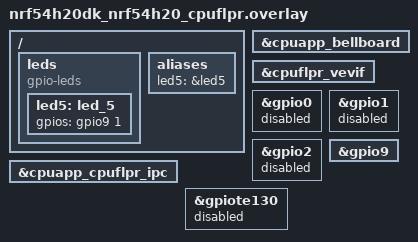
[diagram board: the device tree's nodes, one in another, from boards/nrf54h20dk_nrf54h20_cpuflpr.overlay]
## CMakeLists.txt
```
#
# Copyright (c) 2024 Nordic Semiconductor ASA
#
# SPDX-License-Identifier: LicenseRef-Nordic-5-Clause
#

cmake_minimum_required(VERSION 3.20.0)

find_package(Zephyr REQUIRED HINTS $ENV{ZEPHYR_BASE})
project(sdp_gpio)

sdp_assembly_install(app "${CMAKE_SOURCE_DIR}/src/hrt/hrt.c")

target_sources(app PRIVATE src/main.c)

target_sources_ifdef(CONFIG_SDP_GPIO_BACKEND_ICMSG app PRIVATE src/backend/backend_icmsg.c)
target_sources_ifdef(CONFIG_SDP_GPIO_BACKEND_ICBMSG app PRIVATE src/backend/backend_icmsg.c)
target_sources_ifdef(CONFIG_SDP_GPIO_BACKEND_MBOX app PRIVATE  src/backend/backend_mbox.c)
```

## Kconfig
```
choice SDP_GPIO_BACKEND
	prompt "Backend"
	default SDP_GPIO_BACKEND_ICMSG

config SDP_GPIO_BACKEND_MBOX
	bool "mbox"

config SDP_GPIO_BACKEND_ICMSG
	bool "icmsg"
	select IPC_SERVICE

config SDP_GPIO_BACKEND_ICBMSG
	bool "icbmsg"
	select IPC_SERVICE

endchoice

rsource "../Kconfig"
source "Kconfig.zephyr"
```

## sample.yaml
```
sample:
  name: SDP GPIO application
  description: SDP GPIO application
common:
  integration_platforms:
    - nrf54l15dk/nrf54l15/cpuflpr
tests:
  applications.sdp.gpio.mbox:
    build_only: true
    sysbuild: true
    platform_allow: nrf54l15dk/nrf54l15/cpuflpr
    tags:
      - ci_build
      - sysbuild
      - gpio
    required_snippets:
      - sdp-gpio-mbox

  applications.sdp.gpio.icmsg:
    build_only: true
    sysbuild: true
    platform_allow: nrf54l15dk/nrf54l15/cpuflpr
    tags:
      - ci_build
      - sysbuild
      - gpio
    required_snippets:
      - sdp-gpio-icmsg

  applications.sdp.gpio.icbmsg:
    sysbuild: true
    build_only: true
    platform_allow: nrf54l15dk/nrf54l15/cpuflpr
    tags:
      - ci_build
      - sysbuild
      - gpio
    required_snippets:
      - sdp-gpio-icbmsg
```

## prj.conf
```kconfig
CONFIG_MBOX=y
CONFIG_GPIO=y  

CONFIG_GPIO_NRFX_INTERRUPT=n
CONFIG_NRFX_GPIOTE130=n
CONFIG_NRFX_GPIOTE131=n
```

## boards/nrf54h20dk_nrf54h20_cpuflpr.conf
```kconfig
# Single-threaded
CONFIG_MULTITHREADING=n
CONFIG_KERNEL_MEM_POOL=n
CONFIG_LOG=n

# Drivers and peripherals
CONFIG_I2C=n
CONFIG_WATCHDOG=n
CONFIG_PINCTRL=n
CONFIG_SPI=n
CONFIG_SERIAL=n
CONFIG_FLASH=n

# Power management
CONFIG_PM=n

# Interrupts
CONFIG_DYNAMIC_INTERRUPTS=n
CONFIG_IRQ_OFFLOAD=n

# Memory protection
CONFIG_THREAD_STACK_INFO=n
CONFIG_THREAD_CUSTOM_DATA=n
CONFIG_FPU=n

# Boot
CONFIG_BOOT_BANNER=n

# Console
CONFIG_CONSOLE=n
CONFIG_UART_CONSOLE=n
CONFIG_STDOUT_CONSOLE=n
CONFIG_PRINTK=n
CONFIG_EARLY_CONSOLE=n

# Build
CONFIG_SIZE_OPTIMIZATIONS=y

# No timer support in the kernel
CONFIG_SYS_CLOCK_EXISTS=n

CONFIG_OUTPUT_DISASSEMBLY=y
CONFIG_COMMON_LIBC_MALLOC=n
```

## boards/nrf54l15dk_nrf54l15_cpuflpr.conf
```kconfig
# Single-threaded
CONFIG_MULTITHREADING=n
CONFIG_KERNEL_MEM_POOL=n
CONFIG_LOG=n

# Drivers and peripherals
CONFIG_I2C=n
CONFIG_WATCHDOG=n
CONFIG_GPIO=n
CONFIG_PINCTRL=n
CONFIG_SPI=n
CONFIG_SERIAL=n
CONFIG_FLASH=n

# Power management
CONFIG_PM=n

# Interrupts
CONFIG_DYNAMIC_INTERRUPTS=n
CONFIG_IRQ_OFFLOAD=n

# Memory protection
CONFIG_THREAD_STACK_INFO=n
CONFIG_THREAD_CUSTOM_DATA=n
CONFIG_FPU=n

# Boot
CONFIG_BOOT_BANNER=n
CONFIG_NCS_BOOT_BANNER=n

# Console
CONFIG_CONSOLE=n
CONFIG_UART_CONSOLE=n
CONFIG_STDOUT_CONSOLE=n
CONFIG_PRINTK=n
CONFIG_EARLY_CONSOLE=n

# Build
CONFIG_SIZE_OPTIMIZATIONS=y

# No timer support in the kernel
CONFIG_SYS_CLOCK_EXISTS=n

CONFIG_OUTPUT_DISASSEMBLY=y
CONFIG_COMMON_LIBC_MALLOC=n
```

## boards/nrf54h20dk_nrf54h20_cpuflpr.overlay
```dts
/*
 * Copyright (c) 2024 Nordic Semiconductor ASA
 *
 * SPDX-License-Identifier: LicenseRef-Nordic-5-Clause
 */

&cpuapp_bellboard {
	status = "okay";
};

&cpuflpr_vevif {
	status = "okay";
};

ipc0: &cpuapp_cpuflpr_ipc {
	status = "okay";
};

&gpio0 {
	status = "disabled";
};

&gpio1 {
	status = "disabled";
};

&gpio2 {
	status = "disabled";
};

&gpio9 {
	status = "okay";
};

&gpiote130 {
	status = "disabled";
	/delete-property/gpiote-instance;
};

/ {
	leds {
 		compatible = "gpio-leds";
 
 		led5: led_5 {
 			gpios = <&gpio9 1 GPIO_ACTIVE_HIGH>;
		};
 	};

	aliases {
		led5 = &led5;
	};
};
```

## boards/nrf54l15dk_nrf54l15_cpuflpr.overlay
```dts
/*
 * Copyright (c) 2024 Nordic Semiconductor ASA
 *
 * SPDX-License-Identifier: LicenseRef-Nordic-5-Clause
 */

&cpuflpr_vevif_rx {
	status = "okay";
	interrupts = <16 NRF_DEFAULT_IRQ_PRIORITY>;
	nordic,tasks = <1>;
	nordic,tasks-mask = <0x00010000>;
};

&cpuflpr_vevif_tx {
	status = "okay";
};

&gpio0 {
	status = "disabled";
};

&gpio1 {
	status = "disabled";
};

&gpio2 {
	status = "disabled";
};

&gpiote20 {
	status = "disabled";
};

&gpiote30 {
	status = "disabled";
};

&grtc {
	status = "disabled";
};

&uart20 {
	status = "disabled";
};

&uart30 {
	status = "disabled";
};

&pwm20 {
	status = "disabled";
};
```

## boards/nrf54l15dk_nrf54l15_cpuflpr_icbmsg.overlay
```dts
/*
 * Copyright (c) 2024 Nordic Semiconductor ASA
 *
 * SPDX-License-Identifier: LicenseRef-Nordic-5-Clause
 */

/ {
	soc {
		reserved-memory {
			#address-cells = <1>;
			#size-cells = <1>;

			sram_tx: memory@2003b800 {
				reg = <0x2003b800 0x0800>;
			};

			sram_rx: memory@2003c000 {
				reg = <0x2003c000 0x0800>;
			};
		};
	};

	ipc {
		ipc0: ipc0 {
			compatible = "zephyr,ipc-icbmsg";
			tx-region = <&sram_tx>;
			rx-region = <&sram_rx>;
			tx-blocks = <18>;
			rx-blocks = <16>;
			mboxes = <&cpuflpr_vevif_rx 16>, <&cpuflpr_vevif_tx 20>;
			mbox-names = "rx", "tx";
			status = "okay";
		};
	};
};

&cpuflpr_sram {
	reg = <0x2003c800 DT_SIZE_K(14)>;
	ranges = <0x0 0x2003c800 0x3800>;
};
```

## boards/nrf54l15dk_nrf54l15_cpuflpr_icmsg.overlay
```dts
/*
 * Copyright (c) 2024 Nordic Semiconductor ASA
 *
 * SPDX-License-Identifier: LicenseRef-Nordic-5-Clause
 */

/ {
	soc {
		reserved-memory {
			#address-cells = <1>;
			#size-cells = <1>;

			sram_tx: memory@2003c000 {
				reg = <0x2003c000 0x0800>;
			};

			sram_rx: memory@2003c800 {
				reg = <0x2003c800 0x0800>;
			};
		};
	};

	ipc {
		ipc0: ipc0 {
			compatible = "zephyr,ipc-icmsg";
			tx-region = <&sram_tx>;
			rx-region = <&sram_rx>;
			mboxes = <&cpuflpr_vevif_rx 16>, <&cpuflpr_vevif_tx 20>;
			mbox-names = "rx", "tx";
			status = "okay";
		};
	};
};

&cpuflpr_sram {
	reg = <0x2003d000 DT_SIZE_K(12)>;
	ranges = <0x0 0x2003d000 0x3000>;
};
```

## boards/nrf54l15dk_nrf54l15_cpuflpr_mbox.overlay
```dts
/*
 * Copyright (c) 2024 Nordic Semiconductor ASA
 *
 * SPDX-License-Identifier: LicenseRef-Nordic-5-Clause
 */

/ {
	soc {
		reserved-memory {
			#address-cells = <1>;
			#size-cells = <1>;

			sram_tx: memory@2003c000 {
				reg = <0x2003c000 0x0800>;
			};

			sram_rx: memory@2003c800 {
				reg = <0x2003c800 0x0800>;
			};
		};
	};

	mbox_consumer: mbox_consumer {
		compatible = "vnd,mbox-consumer";
		mboxes = <&cpuflpr_vevif_rx 16>, <&cpuflpr_vevif_tx 20>;
		mbox-names = "rx", "tx";
	};
};

&cpuflpr_rram {
	reg = <0x17a000 DT_SIZE_K(12)>;
};

&cpuflpr_code_partition {
	reg = <0x0 DT_SIZE_K(12)>;
};

&cpuflpr_sram {
	reg = <0x2003d000 DT_SIZE_K(12)>;
	ranges = <0x0 0x2003d000 0x3000>;
};
```

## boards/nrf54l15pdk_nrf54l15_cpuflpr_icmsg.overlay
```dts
/*
 * Copyright (c) 2024 Nordic Semiconductor ASA
 *
 * SPDX-License-Identifier: LicenseRef-Nordic-5-Clause
 */

/ {
	ipc {
		ipc0: ipc0 {
			compatible = "zephyr,ipc-icmsg";
			tx-region = <&sram_tx>;
			rx-region = <&sram_rx>;
			mboxes = <&cpuflpr_vevif_rx 16>, <&cpuflpr_vevif_tx 15>;
			mbox-names = "rx", "tx";
			status = "okay";
		};
	};
};
```

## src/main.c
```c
/*
 * Copyright (c) 2024 Nordic Semiconductor ASA
 *
 * SPDX-License-Identifier: LicenseRef-Nordic-5-Clause
 */

#include "./backend/backend.h"
#include <zephyr/kernel.h>
#include <zephyr/drivers/gpio.h>
#include <zephyr/dt-bindings/gpio/nordic-nrf-gpio.h>
#include <drivers/gpio/nrfe_gpio.h>
#include <hal/nrf_vpr_csr.h>
#include <hal/nrf_vpr_csr_vio.h>
#include <haly/nrfy_gpio.h>

#include <zephyr/drivers/gpio.h>
#define LED5_NODE DT_ALIAS(led5)
static const struct gpio_dt_spec led = GPIO_DT_SPEC_GET(LED5_NODE, gpios);

static nrf_gpio_pin_pull_t get_pull(gpio_flags_t flags)
{
	if (flags & GPIO_PULL_UP) {
		return NRF_GPIO_PIN_PULLUP;
	} else if (flags & GPIO_PULL_DOWN) {
		return NRF_GPIO_PIN_PULLDOWN;
	}

	return NRF_GPIO_PIN_NOPULL;
}

static int gpio_nrfe_pin_configure(uint8_t port, uint16_t pin, uint32_t flags)
{
	if (port != 2) {
		return -EINVAL;
	}

	uint32_t abs_pin = NRF_GPIO_PIN_MAP(port, pin);
	nrf_gpio_pin_pull_t pull = get_pull(flags);
	nrf_gpio_pin_drive_t drive;

	switch (flags & (NRF_GPIO_DRIVE_MSK | GPIO_OPEN_DRAIN)) {
	case NRF_GPIO_DRIVE_S0S1:
		drive = NRF_GPIO_PIN_S0S1;
		break;
	case NRF_GPIO_DRIVE_S0H1:
		drive = NRF_GPIO_PIN_S0H1;
		break;
	case NRF_GPIO_DRIVE_H0S1:
		drive = NRF_GPIO_PIN_H0S1;
		break;
	case NRF_GPIO_DRIVE_H0H1:
		drive = NRF_GPIO_PIN_H0H1;
		break;
	case NRF_GPIO_DRIVE_S0 | GPIO_OPEN_DRAIN:
		drive = NRF_GPIO_PIN_S0D1;
		break;
	case NRF_GPIO_DRIVE_H0 | GPIO_OPEN_DRAIN:
		drive = NRF_GPIO_PIN_H0D1;
		break;
	case NRF_GPIO_DRIVE_S1 | GPIO_OPEN_SOURCE:
		drive = NRF_GPIO_PIN_D0S1;
		break;
	case NRF_GPIO_DRIVE_H1 | GPIO_OPEN_SOURCE:
		drive = NRF_GPIO_PIN_D0H1;
		break;
	default:
		return -EINVAL;
	}

	if (flags & GPIO_OUTPUT_INIT_HIGH) {
		uint16_t outs = nrf_vpr_csr_vio_out_get();

		nrf_vpr_csr_vio_out_set(outs | (BIT(pin)));
	} else if (flags & GPIO_OUTPUT_INIT_LOW) {
		uint16_t outs = nrf_vpr_csr_vio_out_get();

		nrf_vpr_csr_vio_out_set(outs & ~(BIT(pin)));
	}

	nrf_gpio_pin_dir_t dir =
		(flags & GPIO_OUTPUT) ? NRF_GPIO_PIN_DIR_OUTPUT : NRF_GPIO_PIN_DIR_INPUT;
	nrf_gpio_pin_input_t input =
		(flags & GPIO_INPUT) ? NRF_GPIO_PIN_INPUT_CONNECT : NRF_GPIO_PIN_INPUT_DISCONNECT;

	/* Reconfigure the GPIO pin with the specified pull-up/pull-down configuration and drive
	 * strength.
	 */
	nrfy_gpio_reconfigure(abs_pin, &dir, &input, &pull, &drive, NULL);

	if (dir == NRF_GPIO_PIN_DIR_OUTPUT) {
		nrf_vpr_csr_vio_dir_set(nrf_vpr_csr_vio_dir_get() | (BIT(pin)));
	}

	/* Take control of the pin */
	nrfy_gpio_pin_control_select(abs_pin, NRF_GPIO_PIN_SEL_VPR);

	return 0;
}

static void gpio_nrfe_port_set_bits_raw(uint16_t set_mask)
{
	uint16_t outs = nrf_vpr_csr_vio_out_get();

	nrf_vpr_csr_vio_out_set(outs | set_mask);
}

static void gpio_nrfe_port_clear_bits_raw(uint16_t clear_mask)
{
	uint16_t outs = nrf_vpr_csr_vio_out_get();

	nrf_vpr_csr_vio_out_set(outs & ~clear_mask);
}

static void gpio_nrfe_port_toggle_bits(uint16_t toggle_mask)
{
	nrf_vpr_csr_vio_out_toggle_set(toggle_mask);
}

void process_packet(nrfe_gpio_data_packet_t *packet)
{
	if (packet->port != 2) {

		return;
	}

	switch (packet->opcode) {
	case NRFE_GPIO_PIN_CONFIGURE: {
		gpio_nrfe_pin_configure(packet->port, packet->pin, packet->flags);
		break;
	}
	case NRFE_GPIO_PIN_CLEAR: {
		gpio_nrfe_port_clear_bits_raw(packet->pin);
		break;
	}
	case NRFE_GPIO_PIN_SET: {
		gpio_nrfe_port_set_bits_raw(packet->pin);
		break;
	}
	case NRFE_GPIO_PIN_TOGGLE: {
		gpio_pin_toggle_dt(&led);
		gpio_nrfe_port_toggle_bits(packet->pin);
		break;
	}
	default: {
		break;
	}
	}
}

int main(void)
{
	int ret;

	if (!gpio_is_ready_dt(&led)) {
		return 0;
	}

	ret = gpio_pin_configure_dt(&led, GPIO_OUTPUT_ACTIVE);
	if (ret < 0) {
		return 0;
	}

	ret = backend_init(process_packet);
	if (ret < 0) {
		return 0;
	}

	if (!nrf_vpr_csr_rtperiph_enable_check()) {
		nrf_vpr_csr_rtperiph_enable_set(true);
	}

	while (true) {
		k_cpu_idle();
	}

	return 0;
}
```

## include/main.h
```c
/*
 * Copyright (c) 2024 Nordic Semiconductor ASA
 *
 * SPDX-License-Identifier: LicenseRef-Nordic-5-Clause
 */

#ifndef MAIN_H__
#define MAIN_H__

#include <zephyr/kernel.h>
#include <drivers/gpio/nrfe_gpio.h>

#if !defined(CONFIG_GPIO_NRFE_EGPIO_BACKEND_ICMSG) &&    \
	!defined(CONFIG_GPIO_NRFE_EGPIO_BACKEND_MBOX) && \
	!defined(CONFIG_GPIO_NRFE_EGPIO_BACKEND_ICBMSG)
#error "Define communication backend type"
#endif

void process_packet(nrfe_gpio_data_packet_t *packet);
int backend_init(void);

#endif /* MAIN_H__ */
```

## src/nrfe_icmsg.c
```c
/*
 * Copyright (c) 2024 Nordic Semiconductor ASA
 *
 * SPDX-License-Identifier: LicenseRef-Nordic-5-Clause
 */

#include "../include/main.h"
#include <zephyr/ipc/ipc_service.h>

static struct ipc_ept ep;

volatile uint32_t bound_sem = 1;

static void ep_bound(void *priv)
{
	bound_sem = 0;
}

static void ep_recv(const void *data, size_t len, void *priv)
{
	(void)len;
	(void)priv;

	process_packet((nrfe_gpio_data_packet_t *)data);
}

static struct ipc_ept_cfg ep_cfg = {
	.cb = {
		.bound = ep_bound,
		.received = ep_recv,
	},
};

int backend_init(void)
{
	int ret = 0;
	const struct device *ipc0_instance;
	volatile uint32_t delay = 0;

#if !defined(CONFIG_SYS_CLOCK_EXISTS)
	/* Wait a little bit for IPC service to be ready on APP side */
	while (delay < 1000) {
		delay++;
	}
#endif

	ipc0_instance = DEVICE_DT_GET(DT_NODELABEL(ipc0));

	ret = ipc_service_open_instance(ipc0_instance);
	if ((ret < 0) && (ret != -EALREADY)) {
		return ret;
	}

	ret = ipc_service_register_endpoint(ipc0_instance, &ep, &ep_cfg);
	if (ret < 0) {
		return ret;
	}

	/* Wait for endpoint to be bound */
	while (bound_sem != 0) {
	};

	return 0;
}
```

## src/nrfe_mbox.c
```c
/*
 * Copyright (c) 2024 Nordic Semiconductor ASA
 *
 * SPDX-License-Identifier: LicenseRef-Nordic-5-Clause
 */

#include "../include/main.h"
#include <zephyr/drivers/mbox.h>

static const struct mbox_dt_spec rx_channel = MBOX_DT_SPEC_GET(DT_PATH(mbox_consumer), rx);

/**
 * @brief Callback function for when a message is received from the mailbox
 * @param instance Pointer to the mailbox device instance
 * @param channel Unused, but required by the mailbox API
 * @param user_data Pointer to the received message
 * @param msg_data Unused, but required by the mailbox API
 *
 * This function is called when a message is received from the mailbox.
 * It is responsible for handling the received data and logging any errors.
 */
static void mbox_callback(const struct device *instance, uint32_t channel, void *user_data,
			  struct mbox_msg *msg_data)
{
	/* Unused parameters */
	(void)msg_data;

	/* Check for invalid arguments */
	if (user_data == NULL) {
		return;
	}

	nrfe_gpio_mbox_data_t *rx_data = (nrfe_gpio_mbox_data_t *)user_data;

	/* Try and get lock for the shared data structure */
	if (atomic_flag_test_and_set(&rx_data->lock.locked)) {
		/* Return in case lock is not acquired (used by other core)*/
		return;
	}

	nrfe_gpio_data_packet_t *packet = (nrfe_gpio_data_packet_t *)&rx_data->data;

	process_packet(packet);

	/* Clear shared_data.buffer_size (there is no more data available)
	 * This is necessary so that the other core knows that the data has been read
	 */
	rx_data->lock.data_size = 0;

	/* We are finished with the shared data structure, so we can release the lock */
	atomic_flag_clear(&rx_data->lock.locked);
}

/**
 * @brief Initialize the mailbox driver.
 *
 * This function sets up the mailbox receive channel with the callback
 * function specified in the DT node.
 *
 * @return 0 on success, negative error code on failure.
 */
static int mbox_init(void *shared_data)
{
	int ret;

	/* Register the callback function for the mailbox receive channel */
	ret = mbox_register_callback_dt(&rx_channel, mbox_callback, shared_data);
	if (ret < 0) {
		return ret;
	}

	/* Enable the mailbox receive channel */
	return mbox_set_enabled_dt(&rx_channel, true);
}

int backend_init(void)
{
	int ret = 0;

	static nrfe_gpio_mbox_data_t *rx_data =
		(nrfe_gpio_mbox_data_t *)((uint8_t *)(DT_REG_ADDR(DT_NODELABEL(sram_rx))));

	ret = mbox_init((void *)rx_data);
	if (ret < 0) {
		return ret;
	}

	/* clear the buffer locks and their size holders */
	atomic_flag_clear(&rx_data->lock.locked);
	rx_data->lock.data_size = 0;

	return 0;
}
```
